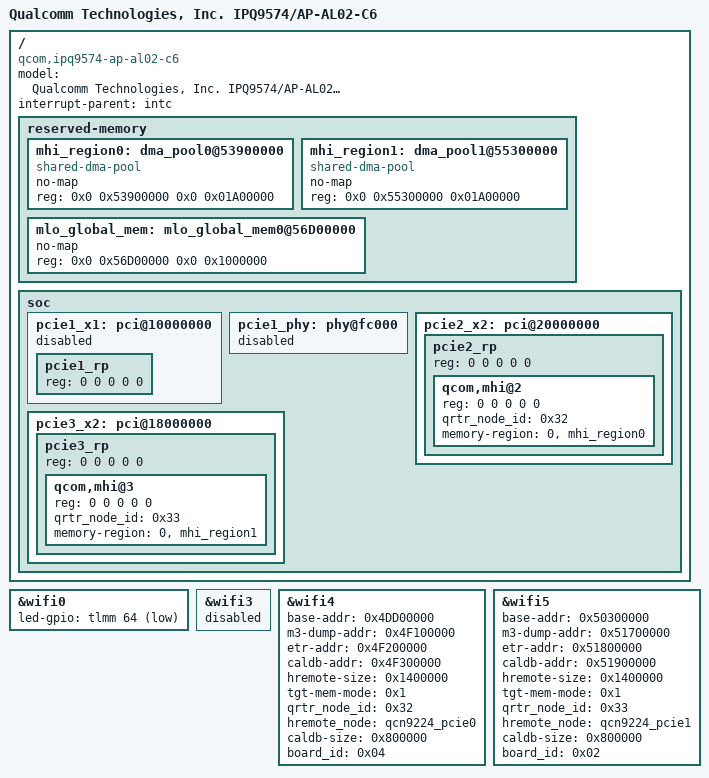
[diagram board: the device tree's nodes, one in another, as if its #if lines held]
// SPDX-License-Identifier: (GPL-2.0+ OR BSD-3-Clause)
/*
 * IPQ9574 AL02-C6 board device tree source
 *
 * Copyright (c) 2020-2021 The Linux Foundation. All rights reserved.
 * Copyright (c) 2022 Qualcomm Innovation Center, Inc. All rights reserved.
 */

/dts-v1/;

#include "ipq9574-al02-c4.dts"

/ {
	#address-cells = <0x2>;
	#size-cells = <0x2>;
	model = "Qualcomm Technologies, Inc. IPQ9574/AP-AL02-C6";
	compatible = "qcom,ipq9574-ap-al02-c6", "qcom,ipq9574-al02", "qcom,ipq9574";
	interrupt-parent = <&intc>;

	/*	Default profile without third WKK memory
	 * +=========+==============+========================+
	 * |        |              |                         |
	 * | Region | Start Offset |          Size           |
	 * |        |              |                         |
	 * +--------+--------------+-------------------------+
	 * |        |              |                         |
	 * |        |              |                         |
	 * |        |              |                         |
	 * |        |              |                         |
	 * | Linux  |  0x42000000  |         123MB           |
	 * |        |              |                         |
	 * |        |              |                         |
	 * |        |              |                         |
	 * +--------+--------------+-------------------------+
	 * |        |              |                         |
	 * |        |              |                         |
	 * | TZ App |  0x49B00000  |           6MB           |
	 * |        |              |                         |
	 * |        |              |                         |
	 * +--------+--------------+-------------------------+
	 * |        |              |                         |
	 * | uboot  |  0x4A100000  |           4MB           |
	 * |        |              |                         |
	 * +--------+--------------+-------------------------+
	 * |  SBL   |  0x4A500000  |           1MB           |
	 * +--------+--------------+-------------------------+
	 * |        |              |                         |
	 * | TZ+HYP |  0x4A600000  |           4MB           |
	 * |        |              |                         |
	 * +--------+--------------+-------------------------+
	 * |  smem  |  0x4AA00000  |           1MB           |
	 * +--------+--------------+-------------------------+
	 * |        |              |                         |
	 * |        |              |                         |
	 * | WLAN   |              |                         |
	 * |   Q6   |  0x4AB00000  |          43MB           |
	 * |        |              |                         |
	 * |        |              |                         |
	 * +--------+--------------+-------------------------+
	 * | M3 Dump|  0x4D600000  |           1MB           |
	 * +--------+--------------+-------------------------+
	 * | WLAN   |              |                         |
	 * | Q6 ETR |  0x4D700000  |           1MB           |
	 * | Region |              |                         |
	 * +--------+--------------+-------------------------+
	 * | caldb  |  0x4D800000  |           5MB           |
	 * +--------+--------------+-------------------------+
	 * |        |              |                         |
	 * |  Wkk0  |  0x4DD00000  |          46MB           |
	 * |        |              |                         |
	 * +--------+--------------+-------------------------+
	 * |        |              |                         |
	 * |  Wkk1  |  0x50B00000  |          46MB           |
	 * |        |              |                         |
	 * +--------+--------------+-------------------------+
	 * |        |              |                         |
	 * |  MHI0  |  0x53900000  |          26MB           |
	 * |        |              |                         |
	 * +--------+--------------+-------------------------+
	 * |        |              |                         |
	 * |  MHI1  |  0x55300000  |          26MB           |
	 * |        |              |                         |
	 * +--------+--------------+-------------------------+
	 * |        |              |                         |
	 * |  MLO   |  0x56D00000  |          16MB           |
	 * |        |              |                         |
	 * +=================================================+
	 * |                                                 |
	 * |                                                 |
	 * |                                                 |
	 * |            Rest of memory for Linux             |
	 * |                                                 |
	 * |                                                 |
	 * |                                                 |
	 * +=================================================+
	 */

	reserved-memory {
		/* Remove Wkk2, MHI2 and rearrange below memories */
		/delete-node/ qcn9224_pcie2@53900000;
		/delete-node/ dma_pool0@56700000;
		/delete-node/ dma_pool1@58100000;
		/delete-node/ dma_pool2@59B00000;
		/delete-node/ mlo_global_mem0@5B500000;
		mhi_region0: dma_pool0@53900000{
			compatible = "shared-dma-pool";
			no-map;
			reg = <0x0 0x53900000 0x0 0x01A00000>;
		};

		mhi_region1: dma_pool1@55300000{
			compatible = "shared-dma-pool";
			no-map;
			reg = <0x0 0x55300000 0x01A00000>;
		};

		mlo_global_mem: mlo_global_mem0@56D00000 {
			no-map;
			reg = <0x0 0x56D00000 0x0 0x1000000>;
		};
	};

	soc {
		pcie1_x1: pci@10000000 {
			status = "disabled";
			/delete-node/ pcie1_rp;
			pcie1_rp {
				reg = <0 0 0 0 0>;
			};
		};

		pcie1_phy: phy@fc000 {
			status = "disabled";
		};

		pcie2_x2: pci@20000000 {
			/delete-node/ pcie2_rp;
			pcie2_rp {
				reg = <0 0 0 0 0>;

				qcom,mhi@2 {
					reg = <0 0 0 0 0>;
					qrtr_node_id = <0x32>;
					memory-region = <0>,<&mhi_region0>;
				};
			};
		};

		pcie3_x2: pci@18000000 {
			/delete-node/ pcie3_rp;
			pcie3_rp {
				reg = <0 0 0 0 0>;

				qcom,mhi@3 {
					reg = <0 0 0 0 0>;
					qrtr_node_id = <0x33>;
					memory-region = <0>,<&mhi_region1>;
				};
			};
		};
	};
};

&wifi0 {
	/* Enable IPQ9574 integratd 2G Radio */
	led-gpio = <&tlmm 64 1>;
	status = "ok";
};

&wifi3 {
	/* QCN9224 2G on PCI1 is disabled for AL02-C6 */
	/delete-property/ hremote_node;
	status = "disabled";
};

&wifi4 {
#if !defined(__IPQ_MEM_PROFILE_256_MB__)
#ifdef __IPQ_MEM_PROFILE_512_MB__
	/* qcn9224 tgt-mem-mode=1 layout - 38MB
	 * +=========+==============+=========+
	 * |  Region | Start Offset |   Size  |
	 * +---------+--------------+---------+
	 * | HREMOTE |  0x4DD00000  |   20MB  |
	 * +---------+--------------+---------+
	 * | M3 Dump |  0x4F100000  |   1MB   |
	 * +---------+--------------+---------+
	 * |   ETR   |  0x4F200000  |   1MB   |
	 * +---------+--------------+---------+
	 * |  Caldb  |  0x4F300000  |   8MB   |
	 * +==================================+
	 */
	base-addr = <0x4DD00000>;
	m3-dump-addr = <0x4F100000>;
	etr-addr = <0x4F200000>;
	caldb-addr = <0x4F300000>;
	hremote-size = <0x1400000>;
	tgt-mem-mode = <0x1>;
#else
	/* qcn9224 tgt-mem-mode=0 layout - 46MB
	 * +=========+==============+=========+
	 * |  Region | Start Offset |   Size  |
	 * +---------+--------------+---------+
	 * | HREMOTE |  0x4DD00000  |   36MB  |
	 * +---------+--------------+---------+
	 * | M3 Dump |  0x50100000  |   1MB   |
	 * +---------+--------------+---------+
	 * |   ETR   |  0x50200000  |   1MB   |
	 * +---------+--------------+---------+
	 * |  Caldb  |  0x50300000  |   8MB   |
	 * +==================================+
	 */
	base-addr = <0x4DD00000>;
	m3-dump-addr = <0x50100000>;
	etr-addr = <0x50200000>;
	caldb-addr = <0x50300000>;
	hremote-size = <0x2400000>;
	tgt-mem-mode = <0x0>;
#endif
	qrtr_node_id = <0x32>;
	hremote_node = <&qcn9224_pcie0>;
	caldb-size = <0x800000>;
	board_id = <0x04>;
	status = "ok";
#endif
};

&wifi5 {
#if !defined(__IPQ_MEM_PROFILE_256_MB__)
#ifdef __IPQ_MEM_PROFILE_512_MB__
	/* qcn9224 tgt-mem-mode=1 layout - 38MB
	 * +=========+==============+=========+
	 * |  Region | Start Offset |   Size  |
	 * +---------+--------------+---------+
	 * | HREMOTE |  0x50300000  |   20MB  |
	 * +---------+--------------+---------+
	 * | M3 Dump |  0x51700000  |   1MB   |
	 * +---------+--------------+---------+
	 * |   ETR   |  0x51800000  |   1MB   |
	 * +---------+--------------+---------+
	 * |  Caldb  |  0x51900000  |   8MB   |
	 * +==================================+
	 */
	base-addr = <0x50300000>;
	m3-dump-addr = <0x51700000>;
	etr-addr = <0x51800000>;
	caldb-addr = <0x51900000>;
	hremote-size = <0x1400000>;
	tgt-mem-mode = <0x1>;
#else
	/* qcn9224 tgt-mem-mode=0 layout - 46MB
	 * +=========+==============+=========+
	 * |  Region | Start Offset |   Size  |
	 * +---------+--------------+---------+
	 * | HREMOTE |  0x50B00000  |   36MB  |
	 * +---------+--------------+---------+
	 * | M3 Dump |  0x52F00000  |   1MB   |
	 * +---------+--------------+---------+
	 * |   ETR   |  0x53000000  |   1MB   |
	 * +---------+--------------+---------+
	 * |  Caldb  |  0x53100000  |   8MB   |
	 * +==================================+
	 */
	base-addr = <0x50B00000>;
	m3-dump-addr = <0x52F00000>;
	etr-addr = <0x53000000>;
	caldb-addr = <0x53100000>;
	hremote-size = <0x2400000>;
	tgt-mem-mode = <0x0>;
#endif
	qrtr_node_id = <0x33>;
	hremote_node = <&qcn9224_pcie1>;
	caldb-size = <0x800000>;
	board_id = <0x02>;
	status = "ok";
#endif
};
